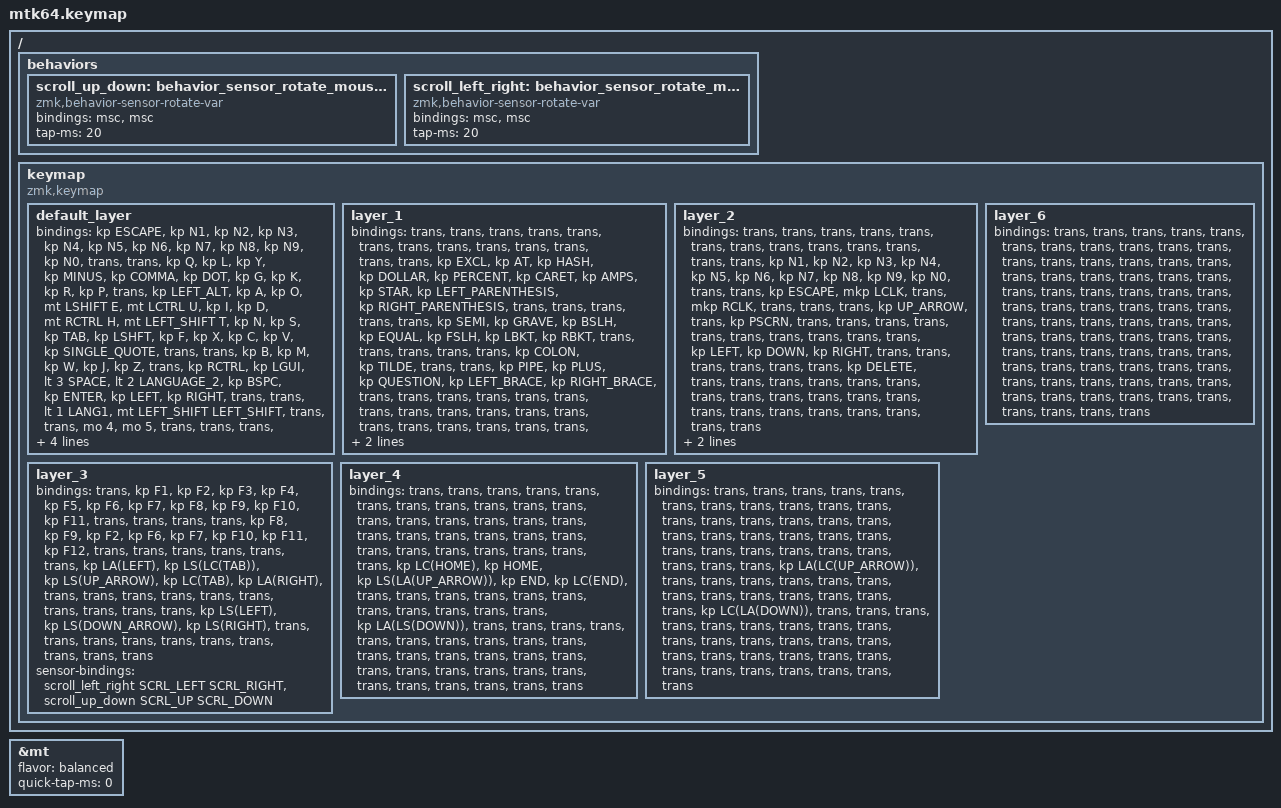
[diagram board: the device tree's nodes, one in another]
#include <input/processors.dtsi>
#include <behaviors.dtsi>
#include <dt-bindings/zmk/keys.h>
#include <dt-bindings/zmk/pointing.h>
#include "keycode_japanese.h"

// スクロール量の設定

#define ZMK_POINTING_DEFAULT_SCRL_VAL 100

&mt {
    flavor = "balanced";
    quick-tap-ms = <0>;
};

// &mkp_input_listener { input-processors = <&zip_temp_layer 6 5000>; };

/ {
    behaviors {
        // 垂直スクロール用のbehaviorの設定

        scroll_up_down: behavior_sensor_rotate_mouse_wheel_up_down {
            compatible = "zmk,behavior-sensor-rotate-var";
            #sensor-binding-cells = <2>;
            bindings = <&msc>, <&msc>;

            tap-ms = <20>; // スクロールのタップ時間
        };

        // 水平スクロール用のbehaviorの設定

        scroll_left_right: behavior_sensor_rotate_mouse_wheel_left_right {
            compatible = "zmk,behavior-sensor-rotate-var";
            #sensor-binding-cells = <2>;
            bindings = <&msc>, <&msc>;

            tap-ms = <20>; // スクロールのタップ時間
        };
    };
};

/ {
    keymap {
        compatible = "zmk,keymap";

        default_layer {
            bindings = <
&kp ESCAPE  &kp N1  &kp N2  &kp N3  &kp N4  &kp N5  &kp N6  &kp N7  &kp N8  &kp N9  &kp N0  &trans  &trans  &kp Q  &kp L  &kp Y  &kp MINUS  &kp COMMA  &kp DOT  &kp G  &kp K  &kp R  &kp P  &trans  &kp LEFT_ALT  &kp A  &kp O  &mt LSHIFT E  &mt LCTRL U  &kp I  &kp D  &mt RCTRL H  &mt LEFT_SHIFT T  &kp N  &kp S  &kp TAB  &kp LSHFT  &kp F  &kp X  &kp C  &kp V  &kp SINGLE_QUOTE  &trans  &trans  &kp B  &kp M  &kp W  &kp J  &kp Z  &trans  &kp RCTRL  &kp LGUI  &lt 3 SPACE  &lt 2 LANGUAGE_2  &kp BSPC  &kp ENTER  &kp LEFT  &kp RIGHT  &trans  &trans  &lt 1 LANG1  &mt LEFT_SHIFT LEFT_SHIFT  &trans  &trans  &mo 4  &mo 5  &trans  &trans  &trans  &trans  &trans  &trans  &trans  &trans  &trans
            >;

            sensor-bindings = <
                &inc_dec_kp LEFT_ARROW RIGHT_ARROW
                &inc_dec_kp UP_ARROW   DOWN_ARROW
            >;
        };

        layer_1 {
            bindings = <
&trans  &trans  &trans  &trans  &trans  &trans  &trans  &trans  &trans  &trans  &trans  &trans  &trans  &kp EXCL  &kp AT  &kp HASH  &kp DOLLAR  &kp PERCENT  &kp CARET  &kp AMPS  &kp STAR  &kp LEFT_PARENTHESIS  &kp RIGHT_PARENTHESIS  &trans  &trans  &trans  &trans  &trans  &kp SEMI  &kp GRAVE  &kp BSLH  &kp EQUAL  &kp FSLH  &kp LBKT  &kp RBKT  &trans  &trans  &trans  &trans  &trans  &kp COLON  &kp TILDE  &trans  &trans  &kp PIPE  &kp PLUS  &kp QUESTION  &kp LEFT_BRACE  &kp RIGHT_BRACE  &trans  &trans  &trans  &trans  &trans  &trans  &trans  &trans  &trans  &trans  &trans  &trans  &trans  &trans  &trans  &trans  &trans  &trans  &trans  &trans  &trans  &trans  &trans  &trans  &trans  &trans
            >;
        };

        layer_2 {
            bindings = <
&trans  &trans  &trans  &trans  &trans  &trans  &trans  &trans  &trans  &trans  &trans  &trans  &trans  &kp N1  &kp N2  &kp N3  &kp N4  &kp N5  &kp N6  &kp N7  &kp N8  &kp N9  &kp N0  &trans  &trans  &kp ESCAPE  &mkp LCLK  &trans  &mkp RCLK  &trans  &trans  &trans  &kp UP_ARROW  &trans  &kp PSCRN  &trans  &trans  &trans  &trans  &trans  &trans  &trans  &trans  &trans  &trans  &kp LEFT  &kp DOWN  &kp RIGHT  &trans  &trans  &trans  &trans  &trans  &trans  &kp DELETE  &trans  &trans  &trans  &trans  &trans  &trans  &trans  &trans  &trans  &trans  &trans  &trans  &trans  &trans  &trans  &trans  &trans  &trans  &trans  &trans
            >;

            sensor-bindings = <
                &inc_dec_kp TAB TAB 
                &inc_dec_kp PG_UP PG_DN
            >;
        };

        layer_3 {
            bindings = <
&trans  &kp F1  &kp F2  &kp F3  &kp F4  &kp F5  &kp F6  &kp F7  &kp F8  &kp F9  &kp F10  &kp F11  &trans  &trans  &trans  &trans  &kp F8  &kp F9  &kp F2  &kp F6  &kp F7  &kp F10  &kp F11  &kp F12  &trans  &trans  &trans  &trans  &trans  &trans  &kp LA(LEFT)  &kp LS(LC(TAB))  &kp LS(UP_ARROW)  &kp LC(TAB)  &kp LA(RIGHT)  &trans  &trans  &trans  &trans  &trans  &trans  &trans  &trans  &trans  &trans  &kp LS(LEFT)  &kp LS(DOWN_ARROW)  &kp LS(RIGHT)  &trans  &trans  &trans  &trans  &trans  &trans  &trans  &trans  &trans  &trans
            >;

            sensor-bindings = <
                &scroll_left_right SCRL_LEFT SCRL_RIGHT
                &scroll_up_down SCRL_UP SCRL_DOWN
            >;
        };

        layer_4 {
            bindings = <
&trans  &trans  &trans  &trans  &trans  &trans  &trans  &trans  &trans  &trans  &trans  &trans  &trans  &trans  &trans  &trans  &trans  &trans  &trans  &trans  &trans  &trans  &trans  &trans  &trans  &trans  &trans  &trans  &trans  &trans  &kp LC(HOME)  &kp HOME  &kp LS(LA(UP_ARROW))  &kp END  &kp LC(END)  &trans  &trans  &trans  &trans  &trans  &trans  &trans  &trans  &trans  &trans  &trans  &kp LA(LS(DOWN))  &trans  &trans  &trans  &trans  &trans  &trans  &trans  &trans  &trans  &trans  &trans  &trans  &trans  &trans  &trans  &trans  &trans  &trans  &trans  &trans  &trans  &trans  &trans  &trans  &trans  &trans  &trans  &trans
            >;
        };

        layer_5 {
            bindings = <
&trans  &trans  &trans  &trans  &trans  &trans  &trans  &trans  &trans  &trans  &trans  &trans  &trans  &trans  &trans  &trans  &trans  &trans  &trans  &trans  &trans  &trans  &trans  &trans  &trans  &trans  &trans  &trans  &trans  &trans  &trans  &trans  &kp LA(LC(UP_ARROW))  &trans  &trans  &trans  &trans  &trans  &trans  &trans  &trans  &trans  &trans  &trans  &trans  &trans  &kp LC(LA(DOWN))  &trans  &trans  &trans  &trans  &trans  &trans  &trans  &trans  &trans  &trans  &trans  &trans  &trans  &trans  &trans  &trans  &trans  &trans  &trans  &trans  &trans  &trans  &trans  &trans  &trans  &trans  &trans  &trans
            >;
        };

        layer_6 {
            bindings = <
&trans  &trans  &trans  &trans  &trans  &trans  &trans  &trans  &trans  &trans  &trans  &trans  &trans  &trans  &trans  &trans  &trans  &trans  &trans  &trans  &trans  &trans  &trans  &trans  &trans  &trans  &trans  &trans  &trans  &trans  &trans  &trans  &trans  &trans  &trans  &trans  &trans  &trans  &trans  &trans  &trans  &trans  &trans  &trans  &trans  &trans  &trans  &trans  &trans  &trans  &trans  &trans  &trans  &trans  &trans  &trans  &trans  &trans  &trans  &trans  &trans  &trans  &trans  &trans  &trans  &trans  &trans  &trans  &trans  &trans  &trans  &trans  &trans  &trans  &trans
            >;
        };
    };
};
